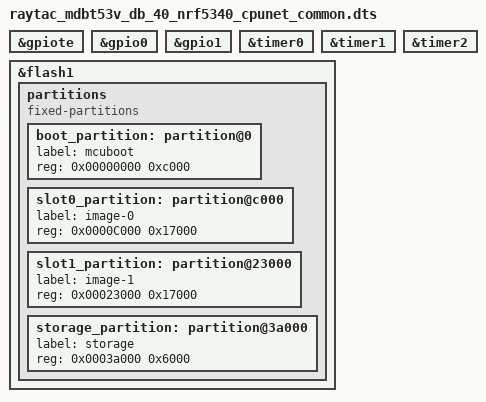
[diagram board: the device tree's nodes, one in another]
/*
 * Copyright (c) 2023 Raytac Corporation
 *
 * SPDX-License-Identifier: Apache-2.0
 */

#include <nordic/nrf5340_cpunet_qkaa.dtsi>

&gpiote {
	status = "okay";
};

&gpio0 {
	status = "okay";
};

&gpio1 {
	status = "okay";
};

&timer0 {
	status = "okay";
};

&timer1 {
	status = "okay";
};

&timer2 {
	status = "okay";
};

&flash1 {

	partitions {
		compatible = "fixed-partitions";
		#address-cells = <1>;
		#size-cells = <1>;

		boot_partition: partition@0 {
			label = "mcuboot";
			reg = <0x00000000 0xc000>;
		};
		slot0_partition: partition@c000 {
			label = "image-0";
			reg = <0x0000C000 0x17000>;
		};
		slot1_partition: partition@23000 {
			label = "image-1";
			reg = <0x00023000 0x17000>;
		};
		storage_partition: partition@3a000 {
			label = "storage";
			reg = <0x0003a000 0x6000>;
		};
	};
};

/* Include shared RAM configuration file */
#include "raytac_mdbt53v_db_40_nrf5340_shared_sram_planning_conf.dts"
